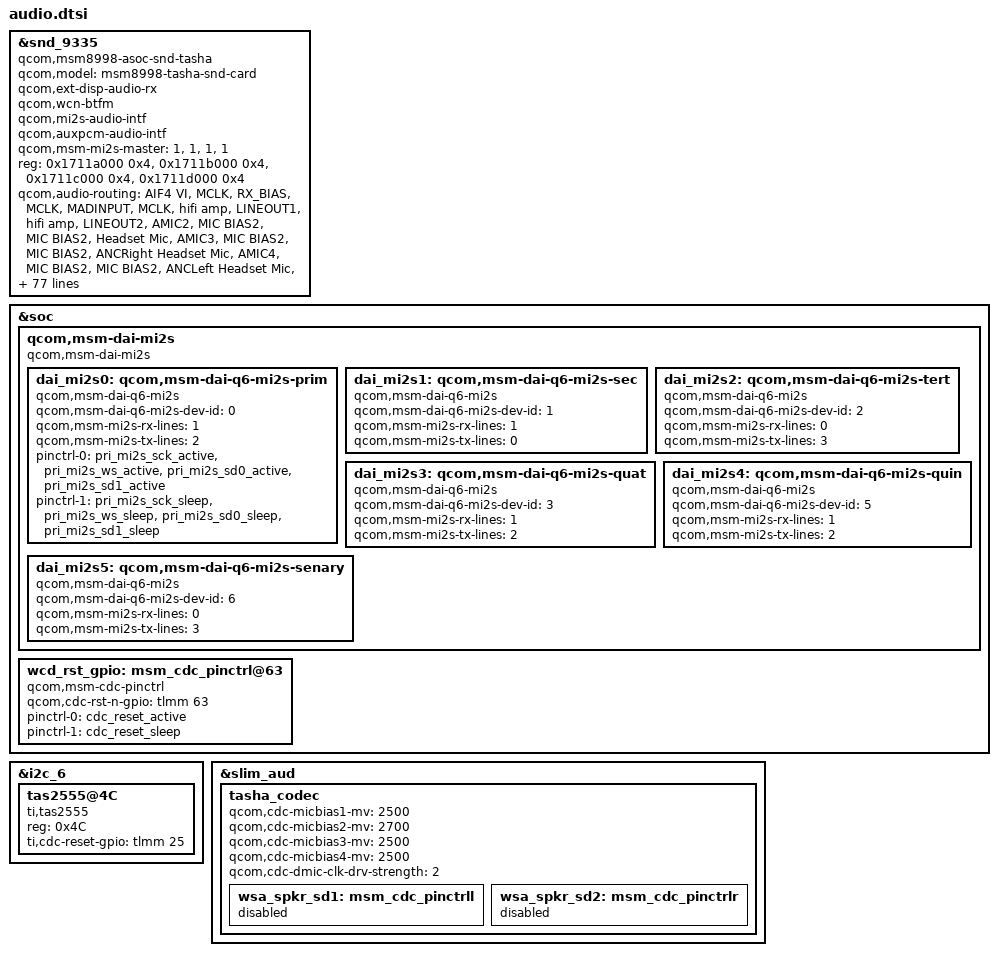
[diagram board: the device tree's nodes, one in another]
	&snd_9335{
		compatible = "qcom,msm8998-asoc-snd-tasha";
		qcom,model = "msm8998-tasha-snd-card";
		qcom,ext-disp-audio-rx;
		qcom,wcn-btfm;
		qcom,mi2s-audio-intf;
		qcom,auxpcm-audio-intf;
		qcom,msm-mi2s-master = <1>, <1>, <1>, <1>;

		reg = <0x1711a000 0x4>,
		      <0x1711b000 0x4>,
		      <0x1711c000 0x4>,
		      <0x1711d000 0x4>;
		reg-names = "lpaif_pri_mode_muxsel",
			    "lpaif_sec_mode_muxsel",
			    "lpaif_tert_mode_muxsel",
			    "lpaif_quat_mode_muxsel";

		qcom,audio-routing =
			"AIF4 VI", "MCLK",
			"RX_BIAS", "MCLK",
			"MADINPUT", "MCLK",
			"hifi amp", "LINEOUT1",
			"hifi amp", "LINEOUT2",
			"AMIC2", "MIC BIAS2",
			"MIC BIAS2", "Headset Mic",
			"AMIC3", "MIC BIAS2",
			"MIC BIAS2", "ANCRight Headset Mic",
			"AMIC4", "MIC BIAS2",
			"MIC BIAS2", "ANCLeft Headset Mic",
			"AMIC5", "MIC BIAS1",
			"MIC BIAS1", "Secondary Mic",
			"AMIC6", "MIC BIAS3",
			"MIC BIAS3", "Handset Mic",
			"DMIC0", "MIC BIAS1",
			"MIC BIAS1", "Digital Mic0",
			"DMIC1", "MIC BIAS1",
			"MIC BIAS1", "Digital Mic1",
			"DMIC2", "MIC BIAS3",
			"MIC BIAS3", "Digital Mic2",
			"DMIC3", "MIC BIAS3",
			"MIC BIAS3", "Digital Mic3",
			"DMIC4", "MIC BIAS4",
			"MIC BIAS4", "Digital Mic4",
			"DMIC5", "MIC BIAS4",
			"MIC BIAS4", "Digital Mic5",
			"SpkrLeft IN", "SPK1 OUT",
			"SpkrRight IN", "SPK2 OUT";


	    /delete-property/ qcom,hph-en0-gpio;
	    /delete-property/ qcom,hph-en1-gpio;
		qcom,msm-mbhc-hphl-swh = <1>;
		qcom,msm-mbhc-gnd-swh = <0>;
		qcom,us-euro-gpios = <&wcd_us_euro_gpio>;
		qcom,swap-en0-gpios = <&tlmm 75 0>;
		qcom,swap-en1-gpios = <&tlmm 80 0>;
		qcom,tasha-mclk-clk-freq = <9600000>;
		asoc-platform = <&pcm0>, <&pcm1>, <&pcm2>, <&voip>, <&voice>,
				<&loopback>, <&compress>, <&hostless>,
				<&afe>, <&lsm>, <&routing>, <&cpe>, <&compr>,
				<&pcm_noirq>, <&cpe3>, <&trans_loopback>;
		asoc-platform-names = "msm-pcm-dsp.0", "msm-pcm-dsp.1",
				"msm-pcm-dsp.2", "msm-voip-dsp",
				"msm-pcm-voice", "msm-pcm-loopback",
				"msm-compress-dsp", "msm-pcm-hostless",
				"msm-pcm-afe", "msm-lsm-client",
				"msm-pcm-routing", "msm-cpe-lsm",
				"msm-compr-dsp", "msm-pcm-dsp-noirq",
				"msm-cpe-lsm.3", "msm-transcode-loopback";
		asoc-cpu = <&dai_hdmi>, <&dai_dp>,
				<&dai_mi2s0>, <&dai_mi2s1>,
				<&dai_mi2s2>, <&dai_mi2s3>,
				<&dai_pri_auxpcm>, <&dai_sec_auxpcm>,
				<&dai_tert_auxpcm>, <&dai_quat_auxpcm>,
				<&sb_0_rx>, <&sb_0_tx>, <&sb_1_rx>, <&sb_1_tx>,
				<&sb_2_rx>, <&sb_2_tx>, <&sb_3_rx>, <&sb_3_tx>,
				<&sb_4_rx>, <&sb_4_tx>, <&sb_5_tx>,
				<&afe_pcm_rx>, <&afe_pcm_tx>, <&afe_proxy_rx>,
				<&afe_proxy_tx>, <&incall_record_rx>,
				<&incall_record_tx>, <&incall_music_rx>,
				<&incall_music_2_rx>, <&sb_5_rx>, <&sb_6_rx>,
				<&sb_7_rx>, <&sb_7_tx>, <&sb_8_tx>,
				<&usb_audio_rx>, <&usb_audio_tx>,
				<&dai_pri_tdm_rx_0>, <&dai_pri_tdm_tx_0>,
				<&dai_sec_tdm_rx_0>, <&dai_sec_tdm_tx_0>,
				<&dai_tert_tdm_rx_0>, <&dai_tert_tdm_tx_0>,
				<&dai_quat_tdm_rx_0>, <&dai_quat_tdm_tx_0>,
				<&proxy_rx>, <&proxy_tx>;
		asoc-cpu-names = "msm-dai-q6-hdmi.8", "msm-dai-q6-dp.24608",
				"msm-dai-q6-mi2s.0", "msm-dai-q6-mi2s.1",
				"msm-dai-q6-mi2s.2", "msm-dai-q6-mi2s.3",
				"msm-dai-q6-auxpcm.1", "msm-dai-q6-auxpcm.2",
				"msm-dai-q6-auxpcm.3", "msm-dai-q6-auxpcm.4",
				"msm-dai-q6-dev.16384", "msm-dai-q6-dev.16385",
				"msm-dai-q6-dev.16386", "msm-dai-q6-dev.16387",
				"msm-dai-q6-dev.16388", "msm-dai-q6-dev.16389",
				"msm-dai-q6-dev.16390", "msm-dai-q6-dev.16391",
				"msm-dai-q6-dev.16392", "msm-dai-q6-dev.16393",
				"msm-dai-q6-dev.16395", "msm-dai-q6-dev.224",
				"msm-dai-q6-dev.225", "msm-dai-q6-dev.241",
				"msm-dai-q6-dev.240", "msm-dai-q6-dev.32771",
				"msm-dai-q6-dev.32772", "msm-dai-q6-dev.32773",
				"msm-dai-q6-dev.32770", "msm-dai-q6-dev.16394",
				"msm-dai-q6-dev.16396", "msm-dai-q6-dev.16398",
				"msm-dai-q6-dev.16399", "msm-dai-q6-dev.16401",
				"msm-dai-q6-dev.28672", "msm-dai-q6-dev.28673",
				"msm-dai-q6-tdm.36864", "msm-dai-q6-tdm.36865",
				"msm-dai-q6-tdm.36880", "msm-dai-q6-tdm.36881",
				"msm-dai-q6-tdm.36896", "msm-dai-q6-tdm.36897",
				"msm-dai-q6-tdm.36912", "msm-dai-q6-tdm.36913",
				"msm-dai-q6-dev.8194", "msm-dai-q6-dev.8195";
		asoc-codec = <&stub_codec>, <&ext_disp_audio_codec>;
		asoc-codec-names = "msm-stub-codec.1",
				   "msm-ext-disp-audio-codec-rx";
		qcom,wsa-max-devs = <0>;
		qcom,wsa-devs = <&wsa881x_211>, <&wsa881x_212>,
				<&wsa881x_213>, <&wsa881x_214>;
		qcom,wsa-aux-dev-prefix = "SpkrLeft", "SpkrRight",
					  "SpkrLeft", "SpkrRight";

	    /delete-node/ msm_cdc_pinctrl@67;
        /delete-node/ msm_cdc_pinctrl@68;
	};

&soc {
	qcom,msm-dai-mi2s {
		compatible = "qcom,msm-dai-mi2s";
		dai_mi2s0: qcom,msm-dai-q6-mi2s-prim {
			compatible = "qcom,msm-dai-q6-mi2s";
			qcom,msm-dai-q6-mi2s-dev-id = <0>;
			qcom,msm-mi2s-rx-lines = <1>;
			qcom,msm-mi2s-tx-lines = <2>;
			pinctrl-names = "default", "sleep";
			pinctrl-0 = <&pri_mi2s_sck_active &pri_mi2s_ws_active &pri_mi2s_sd0_active  &pri_mi2s_sd1_active>;
			pinctrl-1 = <&pri_mi2s_sck_sleep &pri_mi2s_ws_sleep &pri_mi2s_sd0_sleep &pri_mi2s_sd1_sleep>;
		};

		dai_mi2s1: qcom,msm-dai-q6-mi2s-sec {
			compatible = "qcom,msm-dai-q6-mi2s";
			qcom,msm-dai-q6-mi2s-dev-id = <1>;
			qcom,msm-mi2s-rx-lines = <1>;
			qcom,msm-mi2s-tx-lines = <0>;
		};

		dai_mi2s2: qcom,msm-dai-q6-mi2s-tert {
			compatible = "qcom,msm-dai-q6-mi2s";
			qcom,msm-dai-q6-mi2s-dev-id = <2>;
			qcom,msm-mi2s-rx-lines = <0>;
			qcom,msm-mi2s-tx-lines = <3>;
		};

		dai_mi2s3: qcom,msm-dai-q6-mi2s-quat {
			compatible = "qcom,msm-dai-q6-mi2s";
			qcom,msm-dai-q6-mi2s-dev-id = <3>;
			qcom,msm-mi2s-rx-lines = <1>;
			qcom,msm-mi2s-tx-lines = <2>;
		};

		dai_mi2s4: qcom,msm-dai-q6-mi2s-quin {
			compatible = "qcom,msm-dai-q6-mi2s";
			qcom,msm-dai-q6-mi2s-dev-id = <5>;
			qcom,msm-mi2s-rx-lines = <1>;
			qcom,msm-mi2s-tx-lines = <2>;
		};

		dai_mi2s5: qcom,msm-dai-q6-mi2s-senary {
			compatible = "qcom,msm-dai-q6-mi2s";
			qcom,msm-dai-q6-mi2s-dev-id = <6>;
			qcom,msm-mi2s-rx-lines = <0>;
			qcom,msm-mi2s-tx-lines = <3>;
		};
	};
	/delete-node/ sound-tavil;
	/delete-node/ msm_cdc_pinctrl@59;
	/delete-node/ msm_cdc_pinctrl@60;
    /delete-node/ msm_cdc_pinctrl@64;

	wcd_rst_gpio: msm_cdc_pinctrl@63 {
		compatible = "qcom,msm-cdc-pinctrl";
		qcom,cdc-rst-n-gpio = <&tlmm 63 0>;
		pinctrl-names = "aud_active", "aud_sleep";
		pinctrl-0 = <&cdc_reset_active>;
		pinctrl-1 = <&cdc_reset_sleep>;
	};
};

&i2c_6 { /* BLSP1 QUP6 (NFC) */
	  tas2555@4C {
               compatible = "ti,tas2555";
               reg = <0x4C>;
               ti,cdc-reset-gpio = <&tlmm 25 0x00>;
     };
};

&snd_9335 {
	qcom,mbhc-audio-jack-type = "4-pole-jack";
};

&slim_aud{
    tasha_codec {
		    qcom,cdc-micbias1-mv = <2500>;
		    qcom,cdc-micbias2-mv = <2700>;
		    qcom,cdc-micbias3-mv = <2500>;
		    qcom,cdc-micbias4-mv = <2500>;
		    qcom,cdc-dmic-clk-drv-strength = <2>;
		wsa_spkr_sd1: msm_cdc_pinctrll {
		      status = "disabled";
		};

		wsa_spkr_sd2: msm_cdc_pinctrlr {
		      status = "disabled";
		};
    };
};

